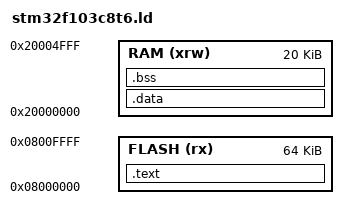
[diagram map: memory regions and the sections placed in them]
MEMORY
{
	FLASH (rx) : ORIGIN = 0x08000000, LENGTH = 64K
	RAM (xrw)  : ORIGIN = 0x20000000, LENGTH = 20K
}

SECTIONS
{
	.text : /*раздел кода и данных только для чтения (FLASH)*/
	{
		. = ALIGN(4); /*Выравнивание, для гарантии начала с адреса кратного 4м*/
		_start_text = .; /*Пометка начала раздела .text*/
		*(.text*) /*Размещение раздела .text*/
		. = ALIGN(4);
		_end_text = .; /*Пометка конца раздела .text*/
		. = ALIGN(4);
		_start_rodata = .; /*Пометка начала раздела .rodata*/
		*(.rodata*) /*Размещение раздела .rodata*/
		/*Хранит значения констант, которые нельзя менять*/
		. = ALIGN(4);
		_end_rodata = .; /*Пометка конца раздела .rodata*/

	} > FLASH /*Разместить описанную "структуру" во FLASH указанный в MEMORY*/
	
	_stored_data = .;
	.data : AT(_stored_data) /*Указание адреза загрузки на исходные значения переменных*/
	/*.data содержит значения инициализированных переменных доступных для чтения-записи*/
	{
		. = ALIGN(4);
		_start_data = .;
		*(.data*)
		. = ALIGN(4);
		_end_data = .;
	} > RAM

	.bss (NOLOAD) : /*Noload гарантирует, что в файле ELF для этого раздела не
	будут сохранены предопределенные значения*/
	/*.bss содержит неинициализированные данные доступные для чтения-записи*/
	{
		. = ALIGN(4);
		_start_bss = .;
		*(.bss*)
		. = ALIGN(4);
		_end_bss = .;
	} > RAM
}
